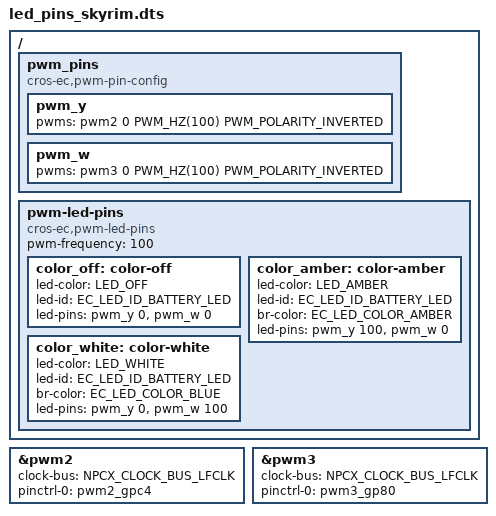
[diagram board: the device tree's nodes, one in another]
/* Copyright 2022 The Chromium OS Authors. All rights reserved.
 * Use of this source code is governed by a BSD-style license that can be
 * found in the LICENSE file.
 */

/ {
	pwm_pins {
		compatible = "cros-ec,pwm-pin-config";

		pwm_y: pwm_y {
			#led-pin-cells = <1>;
			pwms = <&pwm2 0 PWM_HZ(100) PWM_POLARITY_INVERTED>;
		};

		pwm_w: pwm_w {
			#led-pin-cells = <1>;
			pwms = <&pwm3 0 PWM_HZ(100) PWM_POLARITY_INVERTED>;
		};
	};

	pwm-led-pins {
		compatible = "cros-ec,pwm-led-pins";
		pwm-frequency = <100>;

		color_off: color-off {
			led-color = "LED_OFF";
			led-id = "EC_LED_ID_BATTERY_LED";
			led-pins = <&pwm_y 0>,
				   <&pwm_w 0>;
		};

		color_amber: color-amber {
			led-color = "LED_AMBER";
			led-id = "EC_LED_ID_BATTERY_LED";
			br-color = "EC_LED_COLOR_AMBER";
			led-pins = <&pwm_y 100>,
				   <&pwm_w 0>;
		};

		color_white: color-white {
			led-color = "LED_WHITE";
			led-id = "EC_LED_ID_BATTERY_LED";
			br-color = "EC_LED_COLOR_BLUE";
			led-pins = <&pwm_y 0>,
				   <&pwm_w 100>;
		};
	};
};

/* Amber "battery charging" LED */
&pwm2 {
	status = "okay";
	clock-bus = "NPCX_CLOCK_BUS_LFCLK";
	pinctrl-0 = <&pwm2_gpc4>;
	pinctrl-names = "default";
};

/* White "battery full" LED */
&pwm3 {
	status = "okay";
	clock-bus = "NPCX_CLOCK_BUS_LFCLK";
	pinctrl-0 = <&pwm3_gp80>;
	pinctrl-names = "default";
};
